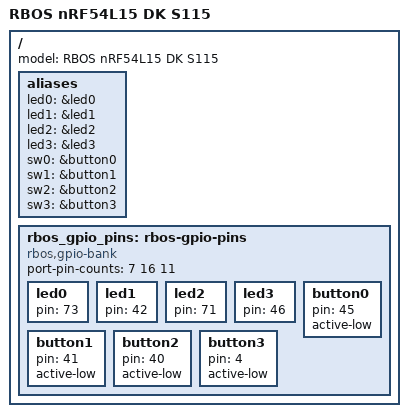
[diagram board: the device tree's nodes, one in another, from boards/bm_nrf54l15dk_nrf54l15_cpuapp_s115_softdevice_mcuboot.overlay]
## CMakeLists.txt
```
cmake_minimum_required(VERSION 3.20.0)

list(PREPEND EXTRA_CONF_FILE "${CMAKE_CURRENT_SOURCE_DIR}/common.conf")
find_package(Zephyr REQUIRED HINTS $ENV{ZEPHYR_BASE})
project(rbos)
zephyr_include_directories(include)

if(NOT DEFINED SYSBUILD)
  message(FATAL_ERROR "This must be built with sysbuild.")
endif()
if(NOT CONFIG_BOARD_BM_NRF54L15DK_NRF54L15_CPUAPP_S115_SOFTDEVICE_MCUBOOT)
  message(FATAL_ERROR "RBOS requires the nRF54L15 DK S115 MCUboot board target.")
endif()
if(NOT CONFIG_MCUBOOT_BOOTLOADER_MODE_FIRMWARE_UPDATER)
  message(FATAL_ERROR "Invalid MCUboot mode selected.")
endif()

zephyr_get(RBOS_PREFLIGHT SYSBUILD LOCAL)
if(RBOS_PREFLIGHT)
  target_sources(app PRIVATE ../tools/bm-build/preflight.c)
  return()
endif()

include(cmake/mrubyc.cmake)
target_include_directories(app PRIVATE ../src/platform/nrf)
target_sources(app PRIVATE ../src/platform/nrf/backend.c)
target_sources(app PRIVATE ../src/platform/nrf/adc.c)
target_sources(app PRIVATE ../src/platform/nrf/gpio.c)
target_sources(app PRIVATE ../src/platform/nrf/button.c)
target_sources(app PRIVATE src/main.c src/runtime.c src/ble.c src/resources.c src/hal/hal.c)
target_sources(app PRIVATE src/resource_probe.c)
```

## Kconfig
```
config NRFX_RESERVED_RESOURCES_HEADER
	default "rbos_reserved_resources.h"

menu "RBOS application"

config RBOS_GPIO
	bool "RBOS board GPIO and Button API"
	default y

config RBOS_PERIPHERAL_EXERCISE
	bool "Run the P2 LED/Button diagnostic task after selftests"
	default y
	depends on RBOS_GPIO && !RBOS_TEST_PROFILE_OOM

choice RBOS_TEST_PROFILE
	prompt "Ruby test profile"
	default RBOS_TEST_PROFILE_SELFTEST

config RBOS_TEST_PROFILE_SELFTEST
	bool "System task and selftests"

config RBOS_TEST_PROFILE_STRESS
	bool "Selftests followed by always-ready spinners"

config RBOS_TEST_PROFILE_OOM
	bool "Retained allocations until fatal pool exhaustion"

endchoice

config RBOS_MAX_VM_COUNT
	int "Maximum number of Ruby VMs"
	range 4 32
	default 8

config RBOS_VM_POOL_SIZE
	int "Ruby VM memory pool size"
	range 16384 131072
	default 65536

config RBOS_TIMESLICE_TICK_COUNT
	int "Ruby VM timeslice (ticks)"
	range 1 255
	default 1

config RBOS_SERVICE_INTERVAL_MS
	int "System service interval (ms)"
	range 1 1000
	default 10

config RBOS_STATS_INTERVAL_MS
	int "Runtime statistics interval (ms)"
	range 100 3600000
	default 10000

config RBOS_VM_NDEBUG
	bool "Disable assertions in mruby/c sources"

module=RBOS
module-str=RBOS
source "$(ZEPHYR_BASE)/subsys/logging/Kconfig.template.log_config"

endmenu

source "Kconfig.zephyr"
```

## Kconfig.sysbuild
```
source "$(ZEPHYR_BASE)/share/sysbuild/Kconfig"

config RBOS_RELEASE
 bool "Require an external release signing key"
 default n
```

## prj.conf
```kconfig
CONFIG_LOG=y
CONFIG_LOG_BACKEND_BM_UARTE=y
CONFIG_CLOCK_CONTROL=y
CONFIG_SOFTDEVICE=y
CONFIG_DEBUG_OPTIMIZATIONS=y
```

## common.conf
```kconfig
CONFIG_LOG=y
CONFIG_LOG_BACKEND_BM_UARTE=y
CONFIG_CLOCK_CONTROL=y
CONFIG_NRFX_SAADC=y
CONFIG_NRFX_GPIOTE=y
CONFIG_NRFX_GPIOTE_NUM_OF_EVT_HANDLERS=4
CONFIG_SOFTDEVICE=y
CONFIG_MAIN_STACK_SIZE=8192
CONFIG_INIT_STACKS=y
CONFIG_BM_TIMER=y
CONFIG_BM_SCHEDULER=y
CONFIG_NRF_SDH_DISPATCH_MODEL_SCHED=y
CONFIG_BM_SCHEDULER_BUF_SIZE=512
CONFIG_NRF_SDH_BLE_LOG_SD_RAM_USAGE=y
CONFIG_NRF_SECURITY=y
CONFIG_MBEDTLS_PSA_CRYPTO_C=y
CONFIG_PSA_WANT_GENERATE_RANDOM=y
CONFIG_BLE_ADV=y
CONFIG_BLE_ADV_RESTART_ON_DISCONNECT=y
CONFIG_BLE_CONN_PARAMS=y
CONFIG_BLE_CONN_PARAMS_AUTO_GAP_CONN_PARAM_UPDATE=n
CONFIG_BLE_CONN_PARAMS_LOG_LEVEL_WRN=y
```

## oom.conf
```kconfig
CONFIG_RBOS_TEST_PROFILE_OOM=y
```

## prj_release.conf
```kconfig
CONFIG_SIZE_OPTIMIZATIONS=y
CONFIG_RBOS_VM_NDEBUG=y
```

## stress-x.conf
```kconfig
CONFIG_RBOS_TEST_PROFILE_STRESS=y
CONFIG_RBOS_TIMESLICE_TICK_COUNT=1
```

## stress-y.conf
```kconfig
CONFIG_RBOS_TEST_PROFILE_STRESS=y
CONFIG_RBOS_SERVICE_INTERVAL_MS=9
```

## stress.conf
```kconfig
CONFIG_RBOS_TEST_PROFILE_STRESS=y
```

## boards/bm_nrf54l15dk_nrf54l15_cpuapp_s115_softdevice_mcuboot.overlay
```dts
/ {
	model = "RBOS nRF54L15 DK S115";
	aliases {
		led0 = &led0;
		led1 = &led1;
		led2 = &led2;
		led3 = &led3;
		sw0 = &button0;
		sw1 = &button1;
		sw2 = &button2;
		sw3 = &button3;
	};
	rbos_gpio_pins: rbos-gpio-pins {
		compatible = "rbos,gpio-bank";
		port-pin-counts = <7 16 11>;
		led0: led0 { pin = <73>; };
		led1: led1 { pin = <42>; };
		led2: led2 { pin = <71>; };
		led3: led3 { pin = <46>; };
		button0: button0 { pin = <45>; active-low; };
		button1: button1 { pin = <41>; active-low; };
		button2: button2 { pin = <40>; active-low; };
		button3: button3 { pin = <4>; active-low; };
	};
};
```

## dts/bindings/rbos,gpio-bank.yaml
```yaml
description: RBOS native GPIO metadata (no Zephyr GPIO driver)
compatible: "rbos,gpio-bank"
properties:
  port-pin-counts:
    type: array
    required: true
child-binding:
  description: Board-reviewed native pin
  properties:
    pin:
      type: int
      required: true
    active-low:
      type: boolean
```

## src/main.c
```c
#include <app_version.h>
#include <board-config.h>
#include <hal/nrf_gpio.h>
#include <zephyr/kernel.h>
#include <zephyr/logging/log.h>
#include <zephyr/logging/log_ctrl.h>
#include "mrubyc.h"
#include "rbos/bindings.h"
#include "backend.h"
#include "embedded.h"
#include "runtime.h"

LOG_MODULE_REGISTER(rbos, CONFIG_RBOS_LOG_LEVEL);
static uint8_t vm_pool[CONFIG_RBOS_VM_POOL_SIZE] __aligned(8);

int main(void)
{
	rbos_stack_paint();
	LOG_INF("RBOS %s", APP_VERSION_EXTENDED_STRING);
	nrf_gpio_cfg_output(BOARD_PIN_LED_0);
	nrf_gpio_pin_write(BOARD_PIN_LED_0, BOARD_LED_ACTIVE_STATE);

	if (rbos_resources_probe()) mrbc_hal_abort("BM scheduler capacity probe failed\n");
	if (rbos_ble_init()) mrbc_hal_abort("BLE initialization failed\n");
	rbos_resources_log();
	mrbc_init(vm_pool, sizeof(vm_pool));
	rbos_define_classes(rbos_nrf_backend());
	rbos_system_define();
	for (unsigned int i = 0; i < rbos_task_count; ++i) {
		mrbc_tcb *task = mrbc_create_task(rbos_tasks[i].bytecode, NULL);
		if (!task) mrbc_hal_abort("Cannot create embedded task\n");
		mrbc_set_task_name(task, rbos_tasks[i].name);
		if (i == 0) {
			rbos_system_set_task(task);
			/* rrt0 sorts lower numeric priorities first (rrt0.c:q_insert_task). */
			mrbc_change_priority(task, 0);
		}
	}
	int status = mrbc_run();
	LOG_ERR("Ruby scheduler returned %d", status);
	mrbc_hal_abort("Ruby scheduler stopped\n");
}
```

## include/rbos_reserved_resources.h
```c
#ifndef RBOS_RESERVED_RESOURCES_H
#define RBOS_RESERVED_RESOURCES_H

#include <nrf_sd_def.h>

#if !defined(CONFIG_SOFTDEVICE_S115) || defined(CONFIG_BT_LL_SOFTDEVICE) || defined(CONFIG_MPSL)
#error "RBOS resource reservations require the standalone S115 SoftDevice"
#endif

#define NRFX_DPPI00_CHANNELS_USED_BY_BT_CTLR SD_DPPIC00_CHANNELS_USED
#define NRFX_DPPI10_CHANNELS_USED_BY_BT_CTLR SD_DPPIC10_CHANNELS_USED
#define NRFX_DPPI20_CHANNELS_USED_BY_BT_CTLR SD_DPPIC20_CHANNELS_USED
#define NRFX_PPIB_00_10_CHANNELS_USED_BY_BT_CTLR \
  (SD_PPIB00_CHANNELS_USED | SD_PPIB10_CHANNELS_USED)
#define NRFX_PPIB_11_21_CHANNELS_USED_BY_BT_CTLR \
  (SD_PPIB11_CHANNELS_USED | SD_PPIB21_CHANNELS_USED)

#include <nrfx_reserved_resources_ncs.h>

#endif
```

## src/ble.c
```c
#include <string.h>
#include <ble_gatts.h>
#include <bm/bluetooth/ble_adv.h>
#include <bm/softdevice_handler/nrf_sdh.h>
#include <bm/softdevice_handler/nrf_sdh_ble.h>
#include <zephyr/logging/log.h>
#include "runtime.h"

LOG_MODULE_REGISTER(rbos_ble, CONFIG_RBOS_LOG_LEVEL);
BLE_ADV_DEF(advertising);

static void on_ble_event(const ble_evt_t *evt, void *context)
{
	ARG_UNUSED(context);
	uint32_t result = NRF_SUCCESS;
	switch (evt->header.evt_id) {
	case BLE_GAP_EVT_CONNECTED:
		LOG_INF("BLE connected");
		break;
	case BLE_GAP_EVT_DISCONNECTED:
		LOG_INF("BLE disconnected reason=0x%02x", evt->evt.gap_evt.params.disconnected.reason);
		break;
	case BLE_GAP_EVT_PHY_UPDATE_REQUEST:
		LOG_INF("BLE PHY request tx=0x%02x rx=0x%02x",
			evt->evt.gap_evt.params.phy_update_request.peer_preferred_phys.tx_phys,
			evt->evt.gap_evt.params.phy_update_request.peer_preferred_phys.rx_phys);
		break;
	case BLE_GAP_EVT_PHY_UPDATE:
		LOG_INF("BLE PHY update status=0x%02x", evt->evt.gap_evt.params.phy_update.status);
		break;
	case BLE_GAP_EVT_DATA_LENGTH_UPDATE_REQUEST:
		LOG_INF("BLE data length request tx=%u rx=%u",
			evt->evt.gap_evt.params.data_length_update_request.peer_params.max_tx_octets,
			evt->evt.gap_evt.params.data_length_update_request.peer_params.max_rx_octets);
		break;
	case BLE_GAP_EVT_DATA_LENGTH_UPDATE:
		LOG_INF("BLE data length updated tx=%u rx=%u",
			evt->evt.gap_evt.params.data_length_update.effective_params.max_tx_octets,
			evt->evt.gap_evt.params.data_length_update.effective_params.max_rx_octets);
		break;
	case BLE_GATTS_EVT_EXCHANGE_MTU_REQUEST:
		LOG_INF("BLE ATT MTU request rx=%u", evt->evt.gatts_evt.params.exchange_mtu_request.client_rx_mtu);
		break;
	case BLE_GATTS_EVT_SYS_ATTR_MISSING:
		LOG_INF("BLE system attributes missing");
		result = sd_ble_gatts_sys_attr_set(evt->evt.gatts_evt.conn_handle, NULL, 0, 0);
		break;
	case BLE_GAP_EVT_SEC_PARAMS_REQUEST:
		LOG_INF("BLE security parameters requested; pairing unsupported");
		result = sd_ble_gap_sec_params_reply(evt->evt.gap_evt.conn_handle,
			BLE_GAP_SEC_STATUS_PAIRING_NOT_SUPP, NULL, NULL);
		break;
	case BLE_GAP_EVT_SEC_INFO_REQUEST:
		LOG_INF("BLE security information requested; no stored bond");
		result = sd_ble_gap_sec_info_reply(evt->evt.gap_evt.conn_handle, NULL);
		break;
	case BLE_GATTS_EVT_TIMEOUT:
		LOG_INF("BLE GATTS timeout source=%u", evt->evt.gatts_evt.params.timeout.src);
		break;
	default:
		break;
	}
	if (result) LOG_ERR("BLE reply event=0x%04x error=%#x", evt->header.evt_id, result);
}
NRF_SDH_BLE_OBSERVER(rbos_ble, on_ble_event, NULL, USER_LOW);

static void on_adv_event(struct ble_adv *adv, const struct ble_adv_evt *evt)
{
	ARG_UNUSED(adv);
	if (evt->evt_type == BLE_ADV_EVT_ERROR) LOG_ERR("Advertising error %#x", evt->error.reason);
}

int rbos_ble_init(void)
{
	int err = nrf_sdh_enable_request();
	if (err) return err;
	err = nrf_sdh_ble_enable(CONFIG_NRF_SDH_BLE_CONN_TAG);
	if (err) return err;
	ble_gap_conn_sec_mode_t security;
	BLE_GAP_CONN_SEC_MODE_SET_NO_ACCESS(&security);
	uint32_t result = sd_ble_gap_device_name_set(&security, "RBOS", 4);
	if (result) return -EIO;
	struct ble_adv_config config = {
		.conn_cfg_tag = CONFIG_NRF_SDH_BLE_CONN_TAG,
		.evt_handler = on_adv_event,
		.adv_data = {
			.name_type = BLE_ADV_DATA_FULL_NAME,
			.flags = BLE_GAP_ADV_FLAGS_LE_ONLY_GENERAL_DISC_MODE,
		},
	};
	result = ble_adv_init(&advertising, &config);
	if (result) return -EIO;
	result = ble_adv_start(&advertising, BLE_ADV_MODE_FAST);
	return result ? -EIO : 0;
}
```

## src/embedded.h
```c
#ifndef RBOS_EMBEDDED_H
#define RBOS_EMBEDDED_H
#include <stdint.h>
struct rbos_embedded_task {
	const char *name;
	const uint8_t *bytecode;
};
extern const struct rbos_embedded_task rbos_tasks[];
extern const unsigned int rbos_task_count;
#endif
```

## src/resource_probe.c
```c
#include <errno.h>
#include <string.h>
#include <bm/bm_scheduler.h>
#include <zephyr/logging/log.h>
#include "runtime.h"

LOG_MODULE_REGISTER(rbos_probe, CONFIG_RBOS_LOG_LEVEL);
static unsigned int delivered;
static bool corrupt;
static uint8_t payload[64];

static void consume(void *data, size_t length)
{
  ++delivered;
  if (length && memcmp(data, payload, length)) corrupt = true;
}

int rbos_resources_probe(void)
{
  /* Run before SoftDevice enable and VM creation, never against a live SD queue. */
  memset(payload, 0xa5, sizeof(payload));
  const size_t lengths[] = { 0, 16, 64 };
  for (unsigned int i = 0; i < 3; ++i) {
    size_t length = lengths[i];
    unsigned int accepted = 0;
    delivered = 0;
    corrupt = false;
    int result = 0;
    for (; accepted < 64; ++accepted) {
      result = bm_scheduler_defer(consume, length ? payload : NULL, length);
      if (result) break;
    }
    bm_scheduler_process();
    bool valid = (result == -ENOMEM || (result == 0 && accepted == 64)) &&
      accepted > 0 && delivered == accepted && !corrupt;
    if (!bm_scheduler_defer(consume, length ? payload : NULL, length)) {
      bm_scheduler_process();
      valid = valid && delivered == accepted + 1 && !corrupt;
    } else valid = false;
    LOG_INF("scheduler_probe payload=%u accepted=%u delivered=%u exhausted=%u recovered=%u",
      (unsigned int)length, accepted, delivered, result == -ENOMEM, valid);
    if (!valid) return -EIO;
  }
  return 0;
}
```

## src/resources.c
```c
#include <bm/bm_irq.h>
#include <bm/bm_scheduler.h>
#include <bm/softdevice_handler/nrf_sdh_ble.h>
#include <nrfx.h>
#include CONFIG_NRFX_RESERVED_RESOURCES_HEADER
#include <zephyr/logging/log.h>
#include <zephyr/sys/util.h>
#include "runtime.h"

LOG_MODULE_REGISTER(rbos_resources, CONFIG_RBOS_LOG_LEVEL);

BUILD_ASSERT(IS_ENABLED(CONFIG_SOFTDEVICE_S115), "RBOS requires S115");
BUILD_ASSERT(IS_ENABLED(CONFIG_LOG_BACKEND_BM_UARTE), "P2 console requires BM UARTE");
BUILD_ASSERT(!IS_ENABLED(CONFIG_SHELL) && !IS_ENABLED(CONFIG_NFC_T2T_NRFXLIB) &&
             !IS_ENABLED(CONFIG_NFC_T4T_NRFXLIB), "Shell/NFC require a new resource audit");
BUILD_ASSERT(IS_ENABLED(CONFIG_NRF_SDH_DISPATCH_MODEL_SCHED), "RBOS requires SCHED dispatch");
BUILD_ASSERT(IS_ENABLED(CONFIG_BM_SCHEDULER), "RBOS requires the BM scheduler");
BUILD_ASSERT(CONFIG_BM_SCHEDULER_BUF_SIZE >= 512, "BM scheduler heap below audited baseline");
BUILD_ASSERT(IS_ENABLED(CONFIG_ZERO_LATENCY_IRQS) && CONFIG_ZERO_LATENCY_LEVELS == 1 &&
             __NVIC_PRIO_BITS == 3 && BM_IRQ_OFFSET == 2,
             "Ruby HAL requires BASEPRI to mask NVIC priorities 2 through 7");
BUILD_ASSERT(CONFIG_BM_TIMER_IRQ_PRIO >= 2 && CONFIG_BM_TIMER_IRQ_PRIO <= 7,
             "BM timer must use an application IRQ priority");
BUILD_ASSERT(CONFIG_LOG_BACKEND_BM_UARTE_IRQ_PRIO >= 2 &&
             CONFIG_LOG_BACKEND_BM_UARTE_IRQ_PRIO <= 7,
             "Console must use an application IRQ priority");
BUILD_ASSERT((NRFX_GRTC_CONFIG_ALLOWED_CC_CHANNELS_MASK & SD_GRTC_CC_CHANNELS_USED) == 0,
             "GRTC allocator overlaps SoftDevice channels");
BUILD_ASSERT((NRFX_GRTC_CONFIG_ALLOWED_CC_CHANNELS_MASK & BIT(0)) != 0 &&
             (SD_GRTC_CC_CHANNELS_USED & BIT(0)) == 0 && SD_GRTC_IRQn_USED != GRTC_2_IRQn,
             "BM system timer requires GRTC channel 0 and GRTC_2");

#define CHECK_RESERVED(actual, reserved) \
  BUILD_ASSERT(((actual) & (reserved)) == (reserved), "nrfx allocator misses " #reserved)
CHECK_RESERVED(NRFX_DPPI00_CHANNELS_USED, SD_DPPIC00_CHANNELS_USED);
CHECK_RESERVED(NRFX_DPPI10_CHANNELS_USED, SD_DPPIC10_CHANNELS_USED);
CHECK_RESERVED(NRFX_DPPI20_CHANNELS_USED, SD_DPPIC20_CHANNELS_USED);
CHECK_RESERVED(NRFX_PPIB_INTERCONNECT_00_10_CHANNELS_USED,
               SD_PPIB00_CHANNELS_USED | SD_PPIB10_CHANNELS_USED);
CHECK_RESERVED(NRFX_PPIB_INTERCONNECT_11_21_CHANNELS_USED,
               SD_PPIB11_CHANNELS_USED | SD_PPIB21_CHANNELS_USED);

void rbos_resources_log(void)
{
  LOG_INF("resources sched_bytes=%u sched_header=%u service_ms=%u sd_ram=%u",
          (unsigned int)CONFIG_BM_SCHEDULER_BUF_SIZE,
          (unsigned int)sizeof(struct bm_scheduler_event),
          (unsigned int)CONFIG_RBOS_SERVICE_INTERVAL_MS,
          (unsigned int)nrf_sdh_ble_sd_ram_usage_get());
}
```

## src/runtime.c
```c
#include <string.h>
#include <bm/bm_scheduler.h>
#include <zephyr/kernel.h>
#include <zephyr/logging/log.h>
#include <zephyr/logging/log_ctrl.h>
#include "runtime.h"
#include "rbos/native.h"
#include "rbos/bindings.h"

LOG_MODULE_REGISTER(rbos_runtime, CONFIG_RBOS_LOG_LEVEL);
K_THREAD_STACK_DECLARE(z_main_stack, CONFIG_MAIN_STACK_SIZE);
K_KERNEL_STACK_ARRAY_DECLARE(z_interrupt_stacks, CONFIG_MP_MAX_NUM_CPUS, CONFIG_ISR_STACK_SIZE);
static uint8_t *main_painted_end;
static mrbc_tcb *system_task;
static unsigned int pool_max;
static unsigned int idle_count;
static unsigned int service_count;
static unsigned int drain_max_us;
static int64_t last_stats;
static struct rbos_event_queue event_queue;

bool rbos_event_post(const struct rbos_event *event)
{
	unsigned int key = irq_lock();
	bool accepted = rbos_event_queue_push(&event_queue, event);
	irq_unlock(key);
	return accepted;
}

bool rbos_event_take(struct rbos_event *event)
{
	unsigned int key = irq_lock();
	bool available = rbos_event_queue_pop(&event_queue, event);
	irq_unlock(key);
	return available;
}

void rbos_event_snapshot(struct rbos_event_stats *stats)
{
	unsigned int key = irq_lock();
	*stats = (struct rbos_event_stats){ event_queue.size, event_queue.overflow, event_queue.coalesced };
	irq_unlock(key);
}

void rbos_stack_paint(void)
{
	uintptr_t sp = __get_PSP();
	uint8_t *base = (uint8_t *)K_THREAD_STACK_BUFFER(z_main_stack);
	/* Leave the current frame and compiler spills untouched. */
	if (sp > (uintptr_t)base + 256) {
		main_painted_end = (uint8_t *)(sp - 256);
		memset(base, 0xaa, main_painted_end - base);
	}
}

static unsigned int stack_used(const uint8_t *base, size_t size, const uint8_t *end)
{
	const uint8_t *p = base;
	while (p < end && *p == 0xaa) ++p;
	return size - (p - base);
}

void rbos_maintenance(bool service)
{
	if (service) ++service_count;
	else ++idle_count;
	uint32_t drain_start = k_cycle_get_32();
	bm_scheduler_process();
	rbos_bindings_service();
	uint32_t drain_us = k_cyc_to_us_floor32(k_cycle_get_32() - drain_start);
	if (drain_us > drain_max_us) drain_max_us = drain_us;
	for (int i = 0; i < 4; ++i) {
		if (!log_process()) break;
	}
	struct MRBC_ALLOC_STATISTICS pool;
	mrbc_alloc_statistics(&pool);
	if (pool.used > pool_max) pool_max = pool.used;
	int64_t now = k_uptime_get();
	if (now - last_stats < CONFIG_RBOS_STATS_INTERVAL_MS) return;
	last_stats = now;
	struct rbos_tick_stats ticks;
	rbos_tick_take_interval(&ticks);
	const uint8_t *main_base = (uint8_t *)K_THREAD_STACK_BUFFER(z_main_stack);
	const uint8_t *isr_base = (uint8_t *)K_KERNEL_STACK_BUFFER(z_interrupt_stacks[0]);
	unsigned int main_used = stack_used(main_base, CONFIG_MAIN_STACK_SIZE,
		main_painted_end ? main_painted_end : main_base);
	unsigned int isr_used = stack_used(isr_base, CONFIG_ISR_STACK_SIZE,
		isr_base + CONFIG_ISR_STACK_SIZE);
	unsigned int key = irq_lock();
	uint32_t pending = event_queue.size;
	uint32_t overflow = event_queue.overflow;
	uint32_t coalesced = event_queue.coalesced;
	irq_unlock(key);
	LOG_INF("stats tick_us=%u..%u catchups=%u ticks=%u pool=%u/%u main=%u isr=%u idle=%u service=%u drain_us=%u event_pending=%u event_overflow=%u event_coalesced=%u",
		ticks.min_us, ticks.max_us, ticks.catchups, ticks.count, pool_max, pool.total,
		main_used, isr_used, idle_count, service_count, drain_max_us,
		pending, overflow, coalesced);
	drain_max_us = 0;
}

static void system_service(mrbc_vm *vm, mrbc_value v[], int argc)
{
	if (!system_task || vm != &system_task->vm) {
		mrbc_raise(vm, MRBC_CLASS(RuntimeError), "System task only");
		return;
	}
	if (!rbos_require_argc(vm, argc, 0, 0)) return;
	rbos_maintenance(true);
	SET_INT_RETURN(CONFIG_RBOS_SERVICE_INTERVAL_MS);
}

void rbos_system_define(void)
{
	mrbc_class *cls = mrbc_define_class(NULL, "RBOSSystem", NULL);
	mrbc_define_method(NULL, cls, "service", system_service);
}

void rbos_system_set_task(mrbc_tcb *task)
{
	system_task = task;
}
```

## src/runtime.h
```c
#ifndef RBOS_RUNTIME_H
#define RBOS_RUNTIME_H
#include <stdbool.h>
#include "mrubyc.h"
#include "rbos/event_queue.h"
/* Producers must use application IRQ priorities masked by irq_lock (NVIC 2+). */
bool rbos_event_post(const struct rbos_event *event);
/* Foreground consumer; native dispatch is added with each peripheral driver. */
bool rbos_event_take(struct rbos_event *event);
void rbos_event_snapshot(struct rbos_event_stats *stats);
void rbos_stack_paint(void);
void rbos_maintenance(bool service);
void rbos_system_define(void);
void rbos_system_set_task(mrbc_tcb *task);
int rbos_ble_init(void);
void rbos_resources_log(void);
int rbos_resources_probe(void);
#endif
```
